# nrf9120_MLM1 register map
Vendor: Nordic Semiconductor; Series: nrf91; File version: 1
CPU: CM4 r0p1, little endian, MPU, FPU, 3 interrupt priority bits
Registers are 32-bit, read-write, reset 0x0 unless marked. A register's access mark holds for its fields unless they carry their own. Offsets are from the block's base; [hi:lo] are bit positions; lines under a group give offsets from that group; 'fields as' and 'values as' point back to an identical list.

## TWIM0 — I2C compatible Two-Wire Master Interface with EasyDMA 0
Base 0x40008000; alternate view of UARTE0
Same registers: TWIM1 0x40009000 (alternate view of UARTE1)
0x00 TASKS_STARTRX wo — Start TWI receive sequence
0x08 TASKS_STARTTX wo — Start TWI transmit sequence
0x14 TASKS_STOP wo — Stop TWI transaction. Must be issued while the TWI master is not suspended.
0x1C TASKS_SUSPEND wo — Suspend TWI transaction
0x20 TASKS_RESUME wo — Resume TWI transaction
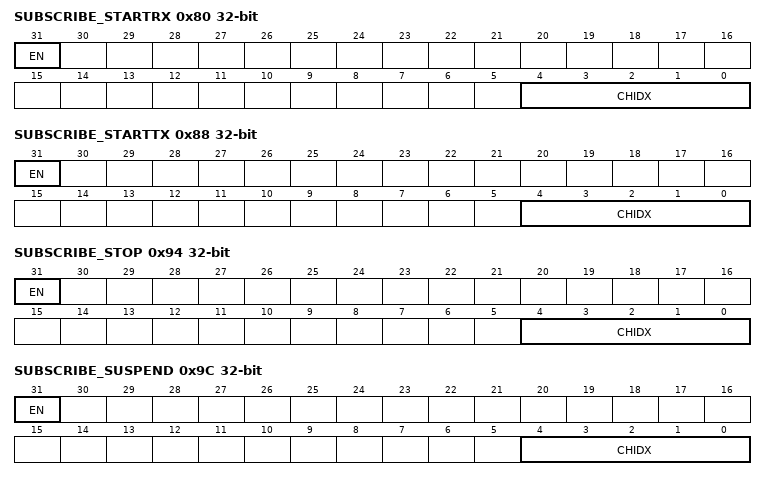
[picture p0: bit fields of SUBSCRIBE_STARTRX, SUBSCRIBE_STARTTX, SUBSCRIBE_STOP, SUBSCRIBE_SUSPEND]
0x80 SUBSCRIBE_STARTRX — Subscribe configuration for TASKS_STARTRX
  [31] EN
    0=Disabled (Disable subscription); 1=Enabled (Enable subscription)
  [4:0] CHIDX — Channel the TASKS_STARTRX will subscribe to.
0x88 SUBSCRIBE_STARTTX — Subscribe configuration for TASKS_STARTTX
  [31] EN
    values as SUBSCRIBE_STARTRX.EN
  [4:0] CHIDX — Channel the TASKS_STARTTX will subscribe to.
0x94 SUBSCRIBE_STOP — Subscribe configuration for TASKS_STOP
  [31] EN
    values as SUBSCRIBE_STARTRX.EN
  [4:0] CHIDX — Channel the TASKS_STOP will subscribe to.
0x9C SUBSCRIBE_SUSPEND — Subscribe configuration for TASKS_SUSPEND
  [31] EN
    values as SUBSCRIBE_STARTRX.EN
  [4:0] CHIDX — Channel the TASKS_SUSPEND will subscribe to.
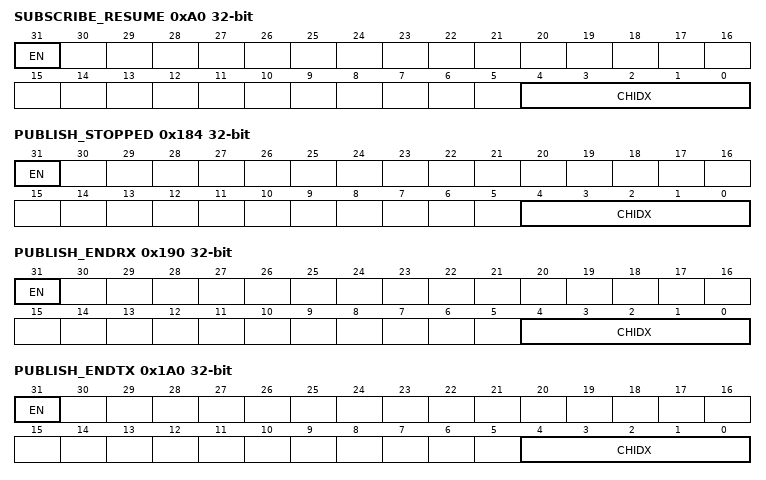
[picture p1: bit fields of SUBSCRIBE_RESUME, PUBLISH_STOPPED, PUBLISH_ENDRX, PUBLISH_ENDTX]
0xA0 SUBSCRIBE_RESUME — Subscribe configuration for TASKS_RESUME
  [31] EN
    values as SUBSCRIBE_STARTRX.EN
  [4:0] CHIDX — Channel the TASKS_RESUME will subscribe to.
0x104 EVENTS_STOPPED — TWI stopped
0x110 EVENTS_ENDRX — End of RXD buffer access by EasyDMA
0x120 EVENTS_ENDTX — END of TXD buffer access by EasyDMA
0x124 EVENTS_ERROR — TWI error
0x138 EVENTS_BB — TWI byte boundary, generated before each byte that is sent or received
0x148 EVENTS_SUSPENDED — Last byte has been sent out after the SUSPEND task has been issued, TWI traffic is now suspended.
0x14C EVENTS_RXSTARTED — Receive sequence started
0x150 EVENTS_TXSTARTED — Transmit sequence started
0x15C EVENTS_LASTRX — Byte boundary, starting to receive the last byte
0x160 EVENTS_LASTTX — Byte boundary, starting to transmit the last byte
0x184 PUBLISH_STOPPED — Publish configuration for EVENTS_STOPPED
  [31] EN
    0=Disabled (Disable publishing); 1=Enabled (Enable publishing)
  [4:0] CHIDX — Channel the EVENTS_STOPPED will subscribe to.
0x190 PUBLISH_ENDRX — Publish configuration for EVENTS_ENDRX
  [31] EN
    values as PUBLISH_STOPPED.EN
  [4:0] CHIDX — Channel the EVENTS_ENDRX will subscribe to.
0x1A0 PUBLISH_ENDTX — Publish configuration for EVENTS_ENDTX
  [31] EN
    values as PUBLISH_STOPPED.EN
  [4:0] CHIDX — Channel the EVENTS_ENDTX will subscribe to.
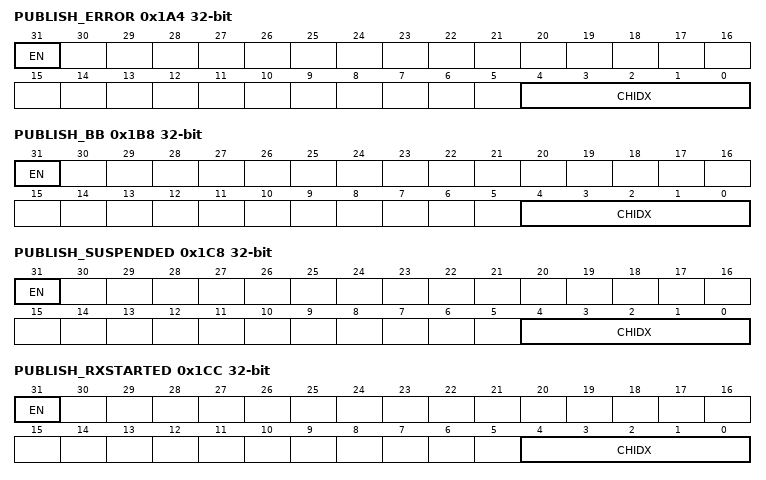
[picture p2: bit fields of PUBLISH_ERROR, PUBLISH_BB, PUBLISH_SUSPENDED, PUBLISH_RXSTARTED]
0x1A4 PUBLISH_ERROR — Publish configuration for EVENTS_ERROR
  [31] EN
    values as PUBLISH_STOPPED.EN
  [4:0] CHIDX — Channel the EVENTS_ERROR will subscribe to.
0x1B8 PUBLISH_BB — Publish configuration for EVENTS_BB
  [31] EN
    values as PUBLISH_STOPPED.EN
  [4:0] CHIDX — Channel the EVENTS_BB will subscribe to.
0x1C8 PUBLISH_SUSPENDED — Publish configuration for EVENTS_SUSPENDED
  [31] EN
    values as PUBLISH_STOPPED.EN
  [4:0] CHIDX — Channel the EVENTS_SUSPENDED will subscribe to.
0x1CC PUBLISH_RXSTARTED — Publish configuration for EVENTS_RXSTARTED
  [31] EN
    values as PUBLISH_STOPPED.EN
  [4:0] CHIDX — Channel the EVENTS_RXSTARTED will subscribe to.
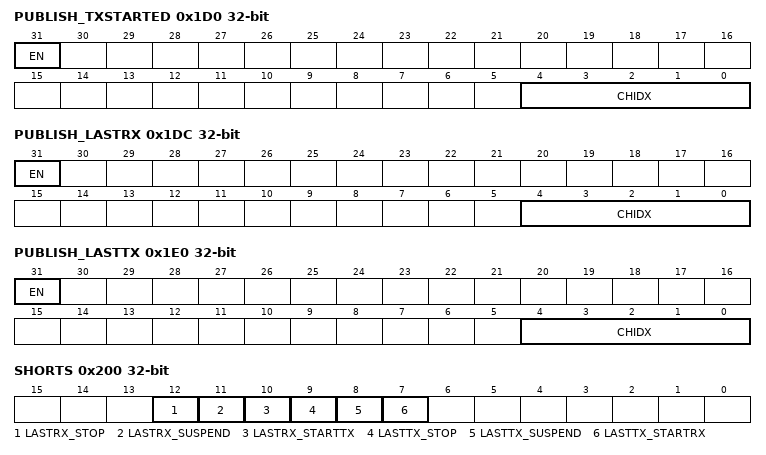
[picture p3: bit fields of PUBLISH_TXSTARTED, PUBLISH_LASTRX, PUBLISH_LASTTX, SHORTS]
0x1D0 PUBLISH_TXSTARTED — Publish configuration for EVENTS_TXSTARTED
  [31] EN
    values as PUBLISH_STOPPED.EN
  [4:0] CHIDX — Channel the EVENTS_TXSTARTED will subscribe to.
0x1DC PUBLISH_LASTRX — Publish configuration for EVENTS_LASTRX
  [31] EN
    values as PUBLISH_STOPPED.EN
  [4:0] CHIDX — Channel the EVENTS_LASTRX will subscribe to.
0x1E0 PUBLISH_LASTTX — Publish configuration for EVENTS_LASTTX
  [31] EN
    values as PUBLISH_STOPPED.EN
  [4:0] CHIDX — Channel the EVENTS_LASTTX will subscribe to.
0x200 SHORTS — Shortcut register
  [all] fields
    0=Disabled (Disable shortcut); 1=Enabled (Enable shortcut)
  [12] LASTRX_STOP — Shortcut between LASTRX event and STOP task
  [11] LASTRX_SUSPEND — Shortcut between LASTRX event and SUSPEND task
  [10] LASTRX_STARTTX — Shortcut between LASTRX event and STARTTX task
  [9] LASTTX_STOP — Shortcut between LASTTX event and STOP task
  [8] LASTTX_SUSPEND — Shortcut between LASTTX event and SUSPEND task
  [7] LASTTX_STARTRX — Shortcut between LASTTX event and STARTRX task
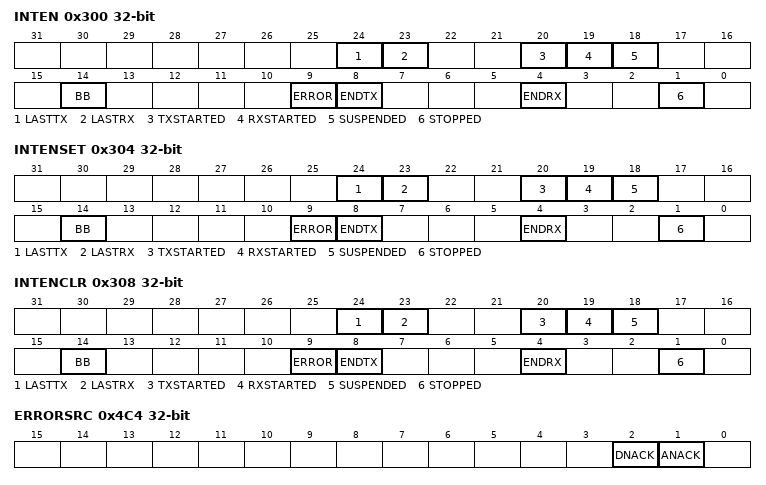
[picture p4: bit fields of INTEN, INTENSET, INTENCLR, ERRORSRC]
0x300 INTEN — Enable or disable interrupt
  [all] fields
    0=Disabled; 1=Enabled
  [24] LASTTX — Enable or disable interrupt for LASTTX event
  [23] LASTRX — Enable or disable interrupt for LASTRX event
  [20] TXSTARTED — Enable or disable interrupt for TXSTARTED event
  [19] RXSTARTED — Enable or disable interrupt for RXSTARTED event
  [18] SUSPENDED — Enable or disable interrupt for SUSPENDED event
  [14] BB — Enable or disable interrupt for BB event
  [9] ERROR — Enable or disable interrupt for ERROR event
  [8] ENDTX — Enable or disable interrupt for ENDTX event
  [4] ENDRX — Enable or disable interrupt for ENDRX event
  [1] STOPPED — Enable or disable interrupt for STOPPED event
0x304 INTENSET — Enable interrupt
  [all] fields
    on read: 0=Disabled (Read: Disabled); 1=Enabled (Read: Enabled) | on write: 1=Set (Enable)
  [24] LASTTX — Write '1' to Enable interrupt for LASTTX event
  [23] LASTRX — Write '1' to Enable interrupt for LASTRX event
  [20] TXSTARTED — Write '1' to Enable interrupt for TXSTARTED event
  [19] RXSTARTED — Write '1' to Enable interrupt for RXSTARTED event
  [18] SUSPENDED — Write '1' to Enable interrupt for SUSPENDED event
  [14] BB — Write '1' to Enable interrupt for BB event
  [9] ERROR — Write '1' to Enable interrupt for ERROR event
  [8] ENDTX — Write '1' to Enable interrupt for ENDTX event
  [4] ENDRX — Write '1' to Enable interrupt for ENDRX event
  [1] STOPPED — Write '1' to Enable interrupt for STOPPED event
0x308 INTENCLR — Disable interrupt
  [all] fields
    on read: 0=Disabled (Read: Disabled); 1=Enabled (Read: Enabled) | on write: 1=Clear (Disable)
  [24] LASTTX — Write '1' to Disable interrupt for LASTTX event
  [23] LASTRX — Write '1' to Disable interrupt for LASTRX event
  [20] TXSTARTED — Write '1' to Disable interrupt for TXSTARTED event
  [19] RXSTARTED — Write '1' to Disable interrupt for RXSTARTED event
  [18] SUSPENDED — Write '1' to Disable interrupt for SUSPENDED event
  [14] BB — Write '1' to Disable interrupt for BB event
  [9] ERROR — Write '1' to Disable interrupt for ERROR event
  [8] ENDTX — Write '1' to Disable interrupt for ENDTX event
  [4] ENDRX — Write '1' to Disable interrupt for ENDRX event
  [1] STOPPED — Write '1' to Disable interrupt for STOPPED event
0x4C4 ERRORSRC write-1-clears — Error source
  [2] DNACK — NACK received after sending a data byte (write '1' to clear)
    0=NotReceived (Error did not occur); 1=Received (Error occurred)
  [1] ANACK — NACK received after sending the address (write '1' to clear)
    values as DNACK
0x500 ENABLE — Enable TWIM
  [3:0] ENABLE — Enable or disable TWIM
    0=Disabled (Disable TWIM); 6=Enabled (Enable TWIM)
0x508 PSEL group — Unspecified
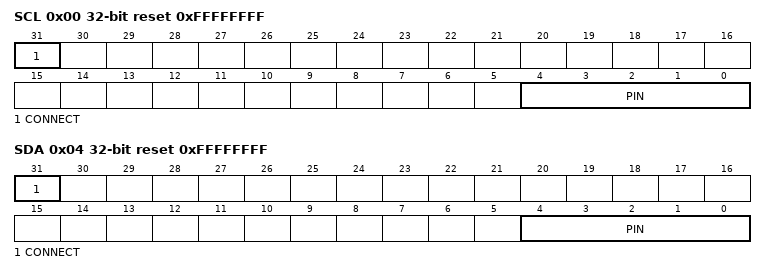
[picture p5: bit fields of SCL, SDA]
  0x00 SCL reset 0xFFFFFFFF — Pin select for SCL signal
    [31] CONNECT — Connection
      1=Disconnected; 0=Connected
    [4:0] PIN — Pin number
  0x04 SDA reset 0xFFFFFFFF — Pin select for SDA signal
    fields as PSEL.SCL
0x524 FREQUENCY reset 0x4000000 — TWI frequency
  [31:0] FREQUENCY — TWI master clock frequency
    0x1980000=K100 (100 kbps); 0x4000000=K250 (250 kbps); 0x6400000=K400 (400 kbps)
0x534 RXD group — RXD EasyDMA channel
  0x00 PTR — Data pointer
  0x04 MAXCNT — Maximum number of bytes in receive buffer
    [7:0] MAXCNT
  0x08 AMOUNT ro — Number of bytes transferred in the last transaction
    [7:0] AMOUNT — Number of bytes transferred in the last transaction. In case of NACK error, includes the NACK'ed byte.
  0x0C LIST — EasyDMA list type
    [2:0] LIST — List type
      0=Disabled (Disable EasyDMA list); 1=ArrayList (Use array list)
0x544 TXD group — TXD EasyDMA channel
  0x00 PTR — Data pointer
  0x04 MAXCNT — Maximum number of bytes in transmit buffer
    [7:0] MAXCNT
  0x08 AMOUNT ro — Number of bytes transferred in the last transaction
    fields as RXD.AMOUNT
  0x0C LIST — EasyDMA list type
    fields as RXD.LIST
0x588 ADDRESS — Address used in the TWI transfer
  [6:0] ADDRESS
0xFFC POWER reset 0x1 — Peripheral power control
  [0] POWER — Peripheral power control. The peripheral and its registers will be reset to its initial state by switching the peripheral off and then back on again.
    0=Disabled (Peripheral is powered off); 1=Enabled (Peripheral is powered on)
